# ESP32-H21 register map
Vendor: ESPRESSIF SYSTEMS (SHANGHAI) CO., LTD.; Series: ESP32 H-Series; File version: 1
CPU: RV32IMAC r0p0, little endian, no MPU, no FPU, 0 interrupt priority bits
Address unit: 32 bits
Registers are 32-bit, read-write, reset 0x0 unless marked. A register's access mark holds for its fields unless they carry their own. Offsets are from the block's base; [hi:lo] are bit positions; {n}, {i} and the like mark numbered series.

## GPIO_SD — Sigma-Delta Modulation
Base 0x60091E00
0x00 GPIO_EXT_CLOCK_GATE — Clock Gating Configure Register
  [0] GPIO_EXT_CLK_EN — Clock enable bit of configuration registers for sigma delta modulation.
0x04 GPIO_EXT_SIGMADELTA_MISC — MISC Register
  [0] GPIO_EXT_SIGMADELTA_CLK_EN — Clock enable bit of sigma delta modulation.
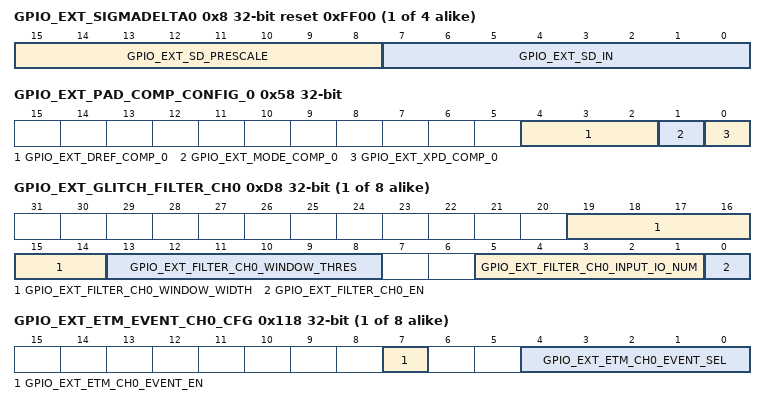
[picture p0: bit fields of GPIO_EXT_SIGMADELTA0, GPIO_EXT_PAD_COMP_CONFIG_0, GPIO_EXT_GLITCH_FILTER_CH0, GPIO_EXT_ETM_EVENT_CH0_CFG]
{0x8+4i} GPIO_EXT_SIGMADELTA{i} (i=0..3) reset 0xFF00 — Duty Cycle Configure Register of SDM{i}
  [15:8] GPIO_EXT_SD_PRESCALE — This field is used to set a divider value to divide APB clock.
  [7:0] GPIO_EXT_SD_IN — This field is used to configure the duty cycle of sigma delta modulation output.
0x58 GPIO_EXT_PAD_COMP_CONFIG_0 — PAD Compare configure Register
  [4:2] GPIO_EXT_DREF_COMP_0 — internal reference voltage tuning bit. 0V to 0.7*VDDPST step 0.1*VDDPST.
  [1] GPIO_EXT_MODE_COMP_0 — 1 to enable external reference from PAD[x]. 0 to enable internal reference, meanwhile PAD[x] can be used as a regular GPIO.
  [0] GPIO_EXT_XPD_COMP_0 — Pad compare enable bit.
0x5C GPIO_EXT_PAD_COMP_FILTER_0 — Zero Detect filter Register
  [31:0] GPIO_EXT_ZERO_DET_FILTER_CNT_0 — Zero Detect filter cycle length
{0xD8+4i} GPIO_EXT_GLITCH_FILTER_CH{i} (i=0..7) — Glitch Filter Configure Register of Channel{i}
  [19:14] GPIO_EXT_FILTER_CH0_WINDOW_WIDTH — Glitch Filter window width.
  [13:8] GPIO_EXT_FILTER_CH0_WINDOW_THRES — Glitch Filter window threshold.
  [5:1] GPIO_EXT_FILTER_CH0_INPUT_IO_NUM — Glitch Filter input io number.
  [0] GPIO_EXT_FILTER_CH0_EN — Glitch Filter channel enable bit.
{0x118+4i} GPIO_EXT_ETM_EVENT_CH{i}_CFG (i=0..7) — Etm Config register of Channel{i}
  [7] GPIO_EXT_ETM_CH0_EVENT_EN — Etm event send enable bit.
  [4:0] GPIO_EXT_ETM_CH0_EVENT_SEL — Etm event channel select gpio.
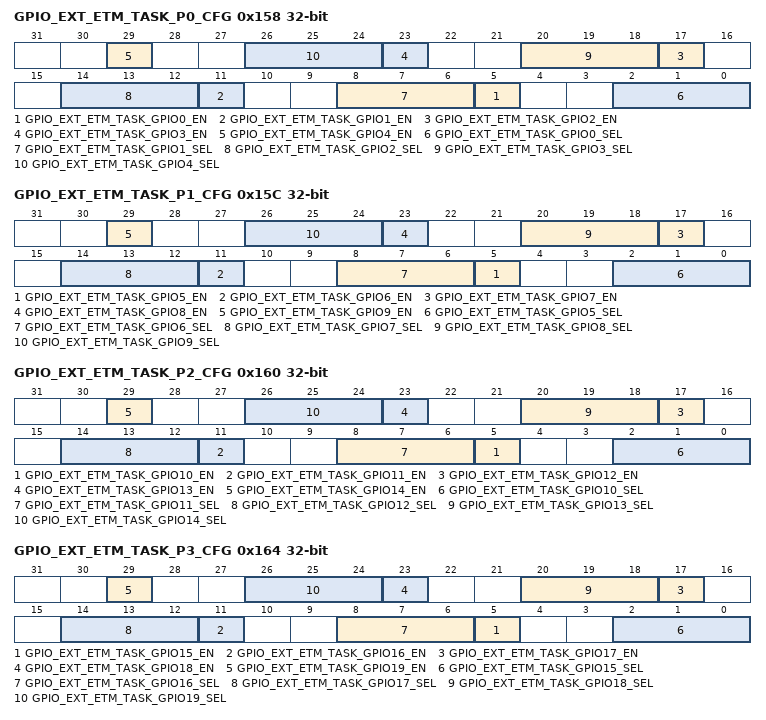
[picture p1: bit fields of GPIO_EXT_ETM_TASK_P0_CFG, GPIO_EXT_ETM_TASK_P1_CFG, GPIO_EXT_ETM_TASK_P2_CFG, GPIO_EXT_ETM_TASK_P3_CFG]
0x158 GPIO_EXT_ETM_TASK_P0_CFG — Etm Configure Register to decide which GPIO been chosen
  [6n+5] GPIO_EXT_ETM_TASK_GPIO{n}_EN (n=0..4) — Enable bit of GPIO response etm task.
  [6n+2:6n] GPIO_EXT_ETM_TASK_GPIO{n}_SEL (n=0..4) — GPIO choose a etm task channel.
0x15C GPIO_EXT_ETM_TASK_P1_CFG — Etm Configure Register to decide which GPIO been chosen
  [6n-25] GPIO_EXT_ETM_TASK_GPIO{n}_EN (n=5..9) — Enable bit of GPIO response etm task.
  [6n-28:6n-30] GPIO_EXT_ETM_TASK_GPIO{n}_SEL (n=5..9) — GPIO choose a etm task channel.
0x160 GPIO_EXT_ETM_TASK_P2_CFG — Etm Configure Register to decide which GPIO been chosen
  [6n-55] GPIO_EXT_ETM_TASK_GPIO{n}_EN (n=10..14) — Enable bit of GPIO response etm task.
  [6n-58:6n-60] GPIO_EXT_ETM_TASK_GPIO{n}_SEL (n=10..14) — GPIO choose a etm task channel.
0x164 GPIO_EXT_ETM_TASK_P3_CFG — Etm Configure Register to decide which GPIO been chosen
  [6n-85] GPIO_EXT_ETM_TASK_GPIO{n}_EN (n=15..19) — Enable bit of GPIO response etm task.
  [6n-88:6n-90] GPIO_EXT_ETM_TASK_GPIO{n}_SEL (n=15..19) — GPIO choose a etm task channel.
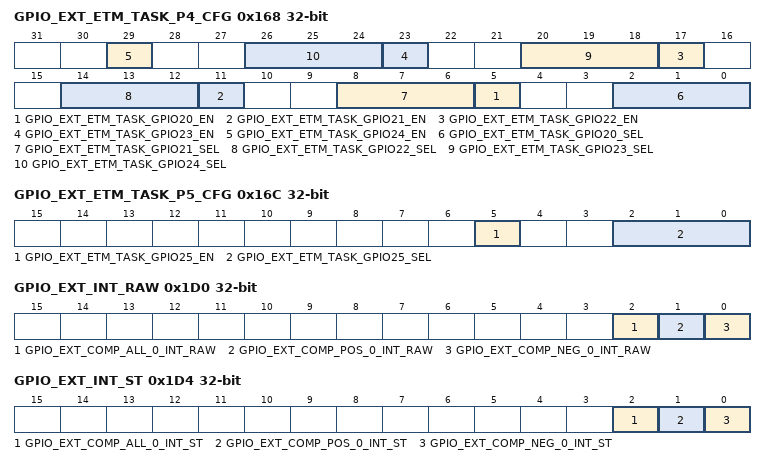
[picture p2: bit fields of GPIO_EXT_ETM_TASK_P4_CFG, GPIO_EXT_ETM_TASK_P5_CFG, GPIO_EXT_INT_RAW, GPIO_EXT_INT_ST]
0x168 GPIO_EXT_ETM_TASK_P4_CFG — Etm Configure Register to decide which GPIO been chosen
  [6n-115] GPIO_EXT_ETM_TASK_GPIO{n}_EN (n=20..24) — Enable bit of GPIO response etm task.
  [6n-118:6n-120] GPIO_EXT_ETM_TASK_GPIO{n}_SEL (n=20..24) — GPIO choose a etm task channel.
0x16C GPIO_EXT_ETM_TASK_P5_CFG — Etm Configure Register to decide which GPIO been chosen
  [5] GPIO_EXT_ETM_TASK_GPIO25_EN — Enable bit of GPIO response etm task.
  [2:0] GPIO_EXT_ETM_TASK_GPIO25_SEL — GPIO choose a etm task channel.
0x1D0 GPIO_EXT_INT_RAW ro — GPIO_EXT interrupt raw register
  [2] GPIO_EXT_COMP_ALL_0_INT_RAW — analog comparator neg or pos edge interrupt raw
  [1] GPIO_EXT_COMP_POS_0_INT_RAW — analog comparator neg edge interrupt raw
  [0] GPIO_EXT_COMP_NEG_0_INT_RAW — analog comparator pos edge interrupt raw
0x1D4 GPIO_EXT_INT_ST ro — GPIO_EXT interrupt masked register
  [2] GPIO_EXT_COMP_ALL_0_INT_ST — analog comparator neg or pos edge interrupt status
  [1] GPIO_EXT_COMP_POS_0_INT_ST — analog comparator neg edge interrupt status
  [0] GPIO_EXT_COMP_NEG_0_INT_ST — analog comparator pos edge interrupt status
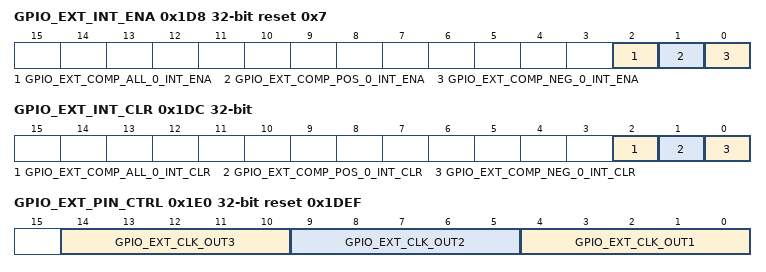
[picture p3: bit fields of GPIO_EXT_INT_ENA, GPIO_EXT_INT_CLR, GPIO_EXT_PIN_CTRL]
0x1D8 GPIO_EXT_INT_ENA reset 0x7 — GPIO_EXT interrupt enable register
  [2] GPIO_EXT_COMP_ALL_0_INT_ENA — analog comparator neg or pos edge interrupt enable
  [1] GPIO_EXT_COMP_POS_0_INT_ENA — analog comparator neg edge interrupt enable
  [0] GPIO_EXT_COMP_NEG_0_INT_ENA — analog comparator pos edge interrupt enable
0x1DC GPIO_EXT_INT_CLR wo — GPIO_EXT interrupt clear register
  [2] GPIO_EXT_COMP_ALL_0_INT_CLR — analog comparator neg or pos edge interrupt clear
  [1] GPIO_EXT_COMP_POS_0_INT_CLR — analog comparator neg edge interrupt clear
  [0] GPIO_EXT_COMP_NEG_0_INT_CLR — analog comparator pos edge interrupt clear
0x1E0 GPIO_EXT_PIN_CTRL reset 0x1DEF — Clock Output Configuration Register
  [14:10] GPIO_EXT_CLK_OUT3 — If you want to output clock for I2S to CLK_OUT_out3, set this register to 0x0. CLK_OUT_out3 can be found in peripheral output signals.
  [9:5] GPIO_EXT_CLK_OUT2 — If you want to output clock for I2S to CLK_OUT_out2, set this register to 0x0. CLK_OUT_out2 can be found in peripheral output signals.
  [4:0] GPIO_EXT_CLK_OUT1 — If you want to output clock for I2S to CLK_OUT_out1, set this register to 0x0. CLK_OUT_out1 can be found in peripheral output signals.
0x1FC GPIO_EXT_VERSION reset 0x2408150 — Version Control Register
  [27:0] GPIO_EXT_DATE — Version control register.
